# STM32WB30CEU6A register map
File version: 1.0
STM32WB30CEU6A,STM32WB50CGU6
Registers are 32-bit, access not given, reset 0x0 unless marked. A register's access mark holds for its fields unless they carry their own. Offsets are from the block's base; lines under a group give offsets from that group; [hi:lo] are bit positions; {n}, {i} and the like mark numbered series; 'fields as' and 'values as' point back to an identical list; <NAME> marks a mode.

## Memory map
0x1FFF8000 FLASH
0x40000000 TIM2
0x40002800 RTCTAMP
0x40002C00 WWDG
0x40003000 IWDG
0x40005400 I2C1
0x40007C00 LPTIM1
0x40009400 LPTIM2
0x40010000 SYSCFG
0x40010100 SYSCFG
0x40012C00 TIM1
0x40013000 SPI1
0x40013800 USART1
0x40014400 TIM16
0x40014800 TIM17
0x40020000 DMA1
0x40020800 DMAMUX
0x40023000 CRC
0x48000000 GPIOA
0x48000400 GPIOB
0x48000800 GPIOC
0x48001000 GPIOE
0x48001C00 GPIOH
0x50040000 ADC
0x58000000 RCC
0x58000400 PWR
0x58000800 EXTI
0x58000C00 IPCC
0x58001000 TRNG
0x58001400 HSEM
0x58001800 AES2
0x58002000 PKA
0x58002400 PKARAM
0x58004000 FLASH

## FLASH
Base 0x1FFF8000
Same registers: FLASH 0x58004000, FLASH 0x58004000
0x00 ACR
  [16] EMPTY, [15] PES, [12] DCRST, [11] ICRST, [10] DCEN, [9] ICEN, [8] PRFTEN, [31:3] s, [2:0] LATENCY
0x08 KEYR
0x0C OPTKEYR
0x10 SR
  [19] PESD, [18] CFGBSY, [16] BSY, [15] OPTVERR, [14] RDERR, [13] OPTNV, [9] FASTERR, [8] MISERR, [7] PGSERR, [6] SIZERR, [5] PGAERR, [4] WRPERR, [3] PROGERR, [31:2] s, [1] OPERR, [0] EOP
0x14 CR
  [31] LOCK, [30] OPTLOCK, [27] OBL_LAUNCH, [26] RDERRIE, [25] ERRIE, [24] EOPIE, [18] FSTPG, [17] OPTSTRT, [16] STRT, [29:11] s, [10:3] PNB, [2] MER, [1] PER, [0] PG
0x18 ECCR
  [31] ECCD, [30] ECCC, [28:26] CPUID, [24] ECCCIE, [20] SYSF_ECC, [29:17] s, [16:0] ADDR_ECC
0x20 OPTR
  [31:29] AGC_TRIM, [27] nBOOT0, [26] nSWBOOT0, [25] SRAM2_RST, [24] SRAM2_PE, [23] nBOOT1, [19] WWDG_SW, [18] IWDG_STBY, [17] IWDG_STOP, [16] IWDG_SW, [28:15] s, [14] nRST_SHDW, [13] nRST_STDB, [12] nRST_STOP, [11:9] BOR_LEV, [8] ESE, [7:0] RDP
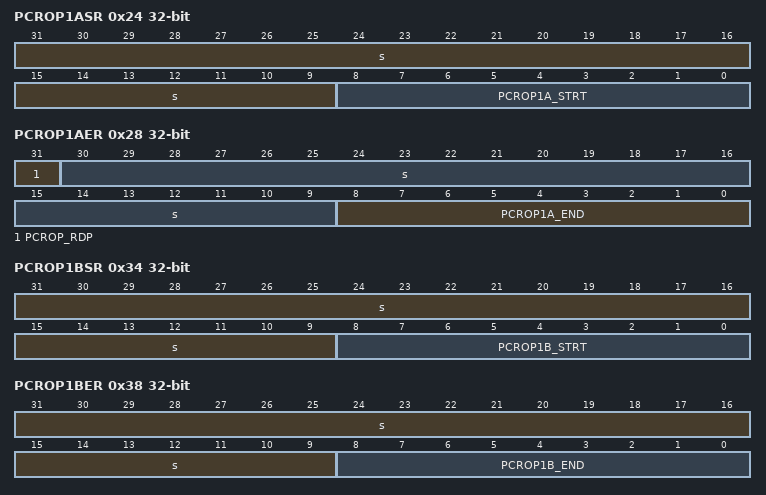
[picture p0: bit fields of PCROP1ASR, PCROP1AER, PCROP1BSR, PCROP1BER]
0x24 PCROP1ASR
  [31:9] s, [8:0] PCROP1A_STRT
0x28 PCROP1AER
  [31] PCROP_RDP, [30:9] s, [8:0] PCROP1A_END
0x2C WRP1AR
  [23:16] WRP1A_END, [31:8] s, [7:0] WRP1A_STRT
0x30 WRP1BR
  [23:16] WRP1B_END, [31:8] s, [7:0] WRP1B_STRT
0x34 PCROP1BSR
  [31:9] s, [8:0] PCROP1B_STRT
0x38 PCROP1BER
  [31:9] s, [8:0] PCROP1B_END
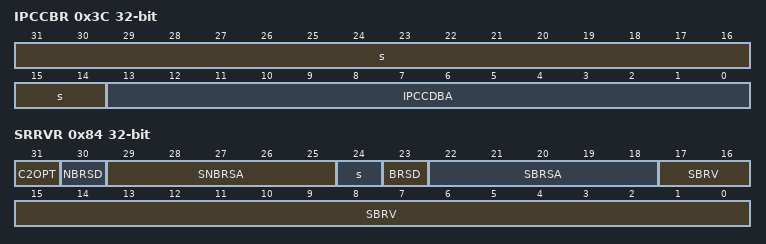
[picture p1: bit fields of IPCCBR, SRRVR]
0x3C IPCCBR
  [31:14] s, [13:0] IPCCDBA
0x5C C2ACR
  [15] PES, [11] ICRST, [9] ICEN, [8] PRFTEN, [31:0] s
0x60 C2SR
  [19] PESD, [18] CFGBSY, [16] BSY, [14] RDERR, [9] FASTERR, [8] MISERR, [7] PGSERR, [6] SIZERR, [5] PGAERR, [4] WRPERR, [3] PROGERR, [31:2] s, [1] OPERR, [0] EOP
0x64 C2CR
  [26] RDERRIE, [25] ERRIE, [24] EOPIE, [18] FSTPG, [16] STRT, [31:11] s, [10:3] PNB, [2] MER, [1] PER, [0] PG
0x80 SFR
  [12] DDS, [31:9] s, [8] FSD, [7:0] SFSA
0x84 SRRVR
  [31] C2OPT, [30] NBRSD, [29:25] SNBRSA, [24] s, [23] BRSD, [22:18] SBRSA, [17:0] SBRV

## TIM2
Base 0x40000000
Same registers: LPTIM2 0x40009400
0x00 CR1
  [11] UIFREMA, [31:10] s, [9:8] CKD, [7] ARPE, [6:5] CMS, [4] DIR, [3] OPM, [2] URS, [1] UDIS, [0] CEN
0x04 CR2
  [7] TI1S, [6:4] MMS, [3] CCDS, [31:0] s
0x08 SMCR
  [15] ETP, [14] ECE, [13:12] ETPS, [11:8] ETF, [7] MSM, [21:4] TS, [31:3] s, [16:0] SMS
0x0C DIER
  [n+8] CC{n}DE (n=1..4), [8] UDE, [6] TIE, [31:5] s, [n] CC{n}IE (n=1..4), [0] UIE
0x10 SR
  [n+8] CC{n}OF (n=1..4), [6] TIF, [31:5] s, [n] CC{n}IF (n=1..4), [0] UIF
0x14 EGR
  [6] TG, [31:5] s, [n] CC{n}G (n=1..4), [0] UG
0x18 CCMR1_OUT
  [31:17] s, [15] OC2CE, [24:12] OC2M, [11] OC2PE, [10] OC2FE, [9:8] CC2S, [7] OC1CE, [16:4] OC1M, [3] OC1PE, [2] OC1FE, [1:0] CC1S
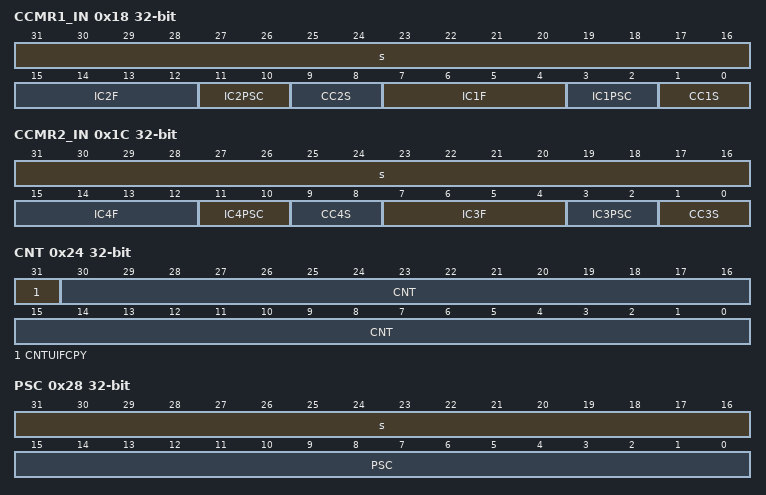
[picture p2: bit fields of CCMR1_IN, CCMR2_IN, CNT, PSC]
0x18 CCMR1_IN
  [31:16] s, [15:12] IC2F, [11:10] IC2PSC, [9:8] CC2S, [7:4] IC1F, [3:2] IC1PSC, [1:0] CC1S
0x1C CCMR2_OUT
  [31:17] s, [15] O24CE, [24:12] OC4M, [11] OC4PE, [10] OC4FE, [9:8] CC4S, [7] OC3CE, [16:4] OC3M, [3] OC3PE, [2] OC3FE, [1:0] CC3S
0x1C CCMR2_IN
  [31:16] s, [15:12] IC4F, [11:10] IC4PSC, [9:8] CC4S, [7:4] IC3F, [3:2] IC3PSC, [1:0] CC3S
0x20 CCER
  [4n-1] CC{n}NP (n=1..4), [4n-3] CC{n}P (n=1..4), [4n-4] CC{n}E (n=1..4), [31:2] s
0x24 CNT
  [31] CNTUIFCPY, [30:0] CNT
0x28 PSC
  [31:16] s, [15:0] PSC
0x2C ARR
{0x30+4i} CCR{i} (i=1..4)
0x48 DCR
  [12:8] DBL, [31:5] s, [4:0] DBA
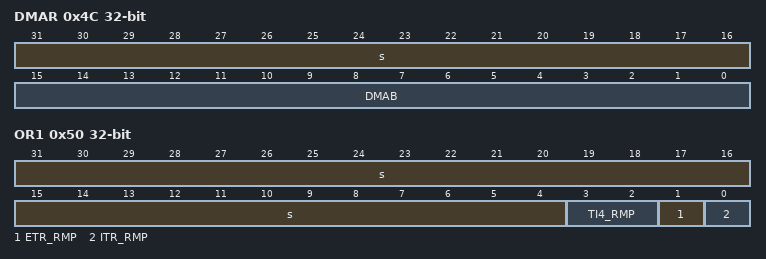
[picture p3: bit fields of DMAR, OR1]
0x4C DMAR
  [31:16] s, [15:0] DMAB
0x50 OR1
  [31:4] s, [3:2] TI4_RMP, [1] ETR_RMP, [0] ITR_RMP
0x60 AF1
  [17:14] ETRSEL, [31:0] s
0x68 TISEL
  [11:8] TI2SEL, [31:4] s, [3:0] TI1SEL
